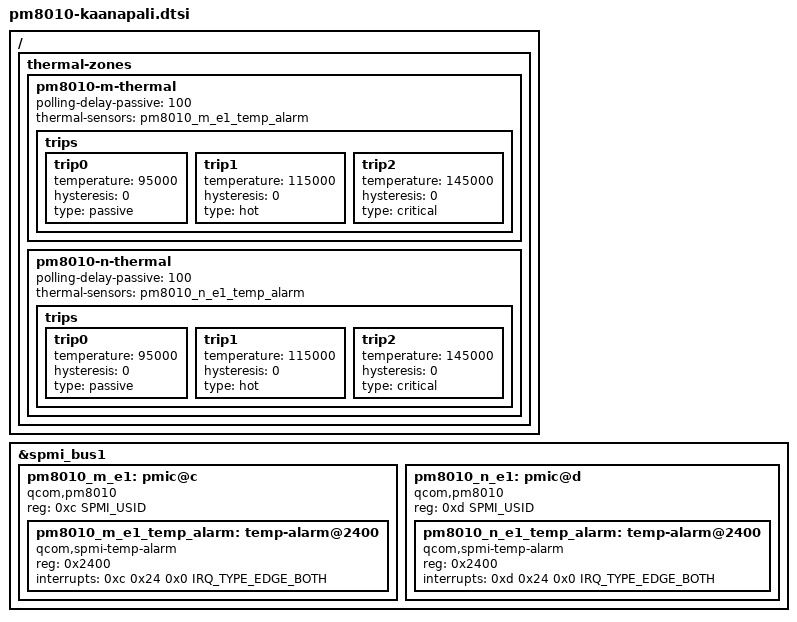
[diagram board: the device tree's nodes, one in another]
// SPDX-License-Identifier: BSD-3-Clause
/*
 * Copyright (c) Qualcomm Technologies, Inc. and/or its subsidiaries.
 */

#include <dt-bindings/interrupt-controller/irq.h>
#include <dt-bindings/spmi/spmi.h>

/ {
	thermal-zones {
		pm8010-m-thermal {
			polling-delay-passive = <100>;

			thermal-sensors = <&pm8010_m_e1_temp_alarm>;

			trips {
				trip0 {
					temperature = <95000>;
					hysteresis = <0>;
					type = "passive";
				};

				trip1 {
					temperature = <115000>;
					hysteresis = <0>;
					type = "hot";
				};

				trip2 {
					temperature = <145000>;
					hysteresis = <0>;
					type = "critical";
				};
			};
		};

		pm8010-n-thermal {
			polling-delay-passive = <100>;

			thermal-sensors = <&pm8010_n_e1_temp_alarm>;

			trips {
				trip0 {
					temperature = <95000>;
					hysteresis = <0>;
					type = "passive";
				};

				trip1 {
					temperature = <115000>;
					hysteresis = <0>;
					type = "hot";
				};

				trip2 {
					temperature = <145000>;
					hysteresis = <0>;
					type = "critical";
				};
			};
		};
	};
};

&spmi_bus1 {
	pm8010_m_e1: pmic@c {
		compatible = "qcom,pm8010", "qcom,spmi-pmic";
		reg = <0xc SPMI_USID>;
		#address-cells = <1>;
		#size-cells = <0>;

		pm8010_m_e1_temp_alarm: temp-alarm@2400 {
			compatible = "qcom,spmi-temp-alarm";
			reg = <0x2400>;
			interrupts = <0xc 0x24 0x0 IRQ_TYPE_EDGE_BOTH>;
			#thermal-sensor-cells = <0>;
		};
	};

	pm8010_n_e1: pmic@d {
		compatible = "qcom,pm8010", "qcom,spmi-pmic";
		reg = <0xd SPMI_USID>;
		#address-cells = <1>;
		#size-cells = <0>;

		pm8010_n_e1_temp_alarm: temp-alarm@2400 {
			compatible = "qcom,spmi-temp-alarm";
			reg = <0x2400>;
			interrupts = <0xd 0x24 0x0 IRQ_TYPE_EDGE_BOTH>;
			#thermal-sensor-cells = <0>;
		};
	};
};
